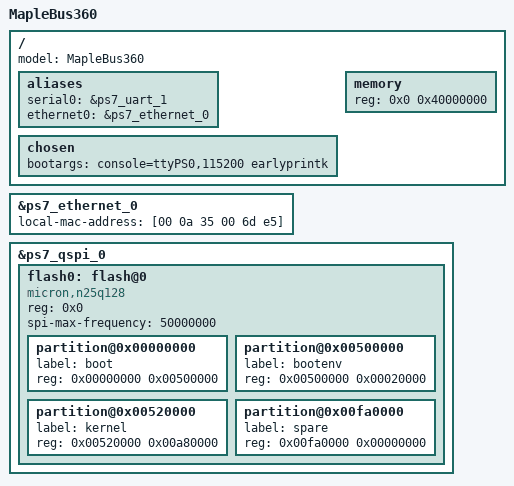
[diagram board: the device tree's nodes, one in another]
/*
 * CAUTION: This file is automatically generated by PetaLinux SDK.
 * DO NOT modify this file
 */

/include/ "ps.dtsi"
/include/ "pl.dtsi"

/ {
	model = "MapleBus360";
	aliases {
		serial0 = &ps7_uart_1;
		ethernet0 = &ps7_ethernet_0;
	};
	chosen {
		bootargs = "console=ttyPS0,115200 earlyprintk";
	};
	memory {
		device_type = "memory";
		reg = <0x0 0x40000000>;
	};
};

&ps7_ethernet_0 {
	local-mac-address = [00 0a 35 00 6d e5];
};

&ps7_qspi_0 {
	#address-cells = <1>;
	#size-cells = <0>;
	flash0: flash@0 {
		compatible = "micron,n25q128";
		reg = <0x0>;
		#address-cells = <1>;
		#size-cells = <1>;
		spi-max-frequency = <50000000>;
		partition@0x00000000 {
			label = "boot";
			reg = <0x00000000 0x00500000>;
		};
		partition@0x00500000 {
			label = "bootenv";
			reg = <0x00500000 0x00020000>;
		};
		partition@0x00520000 {
			label = "kernel";
			reg = <0x00520000 0x00a80000>;
		};
		partition@0x00fa0000 {
			label = "spare";
			reg = <0x00fa0000 0x00000000>;
		};
	};
};

